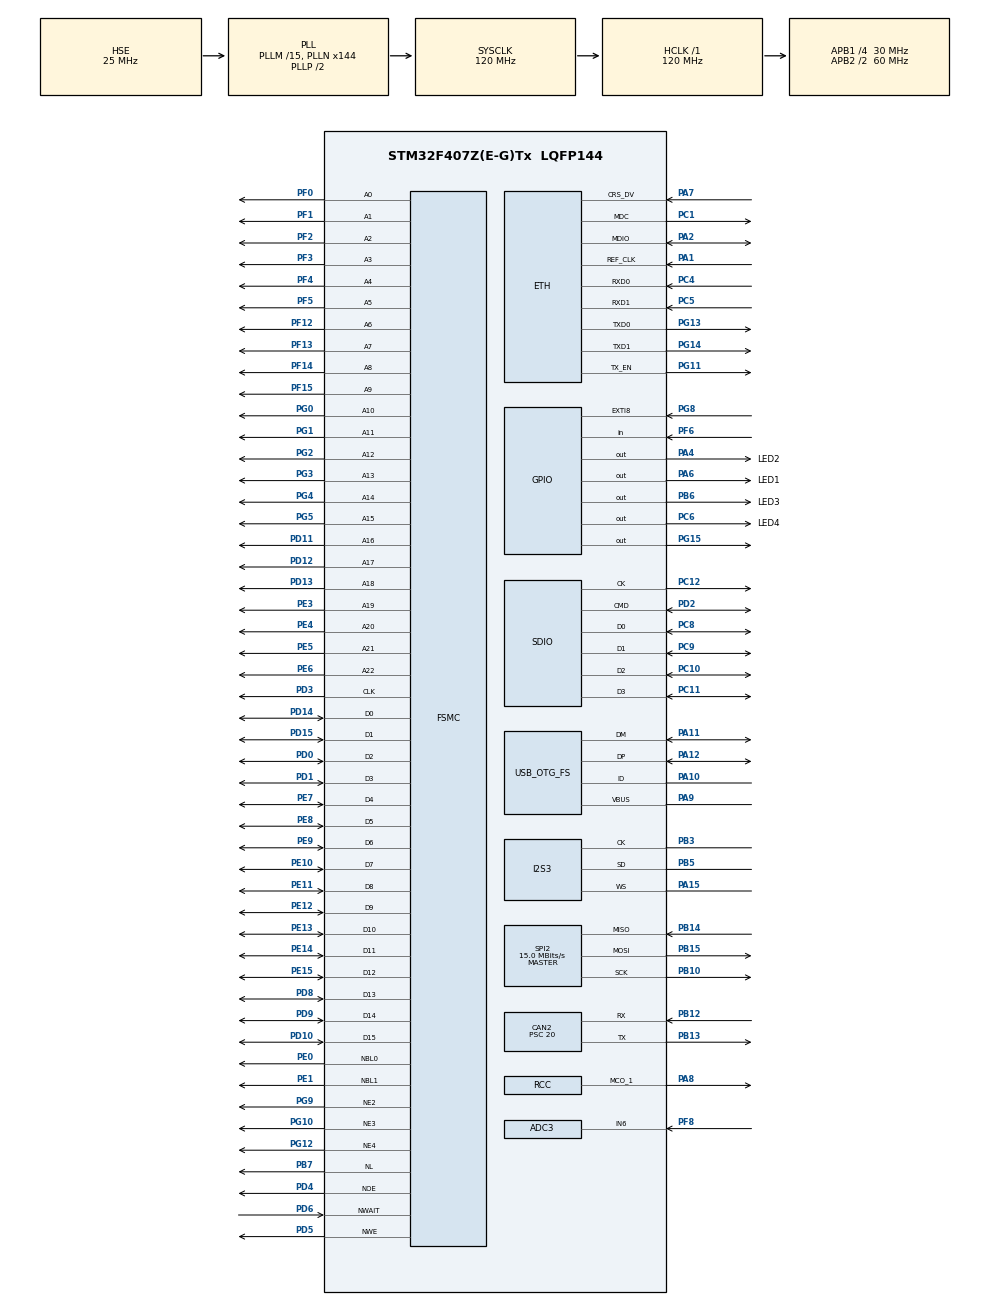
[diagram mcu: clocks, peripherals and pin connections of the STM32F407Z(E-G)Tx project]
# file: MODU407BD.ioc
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ADC3.Channel-0\#ChannelRegularConversion=ADC_CHANNEL_6
ADC3.NbrOfConversionFlag=1
ADC3.Rank-0\#ChannelRegularConversion=1
ADC3.SamplingTime-0\#ChannelRegularConversion=ADC_SAMPLETIME_3CYCLES
CAN2.CalculateBaudRate=499999
CAN2.CalculateTimeBit=2000
CAN2.CalculateTimeQuantum=666.6666666666667
CAN2.Prescaler=20
ETH.MediaInterface=ETH_MEDIA_INTERFACE_RMII
FATFS.BSP.number=1
FATFS0.BSP.STBoard=false
FATFS0.BSP.api=Unknown
FATFS0.BSP.i2caddr=0
FATFS0.BSP.instance=PF6
FATFS0.BSP.ip=GPIO
FATFS0.BSP.mode=Input
FATFS0.BSP.name=Detect_SDIO
FATFS0.BSP.solution=PF6
FREERTOS.Tasks01=mqttTask,0,512,startMqttTask,Default,NULL,Dynamic,NULL,NULL;dispTask,-1,512,startDispTask,Default,NULL,Dynamic,NULL,NULL
FREERTOS.configCHECK_FOR_STACK_OVERFLOW=2
FREERTOS.configENABLE_FPU=1
FREERTOS.configMINIMAL_STACK_SIZE=512
FREERTOS.configUSE_NEWLIB_REENTRANT=1
FSMC.AddressSetupTime1=1
FSMC.BusTurnAroundDuration1=1
FSMC.DataSetupTime1=1
I2S3.AudioFreq=I2S_AUDIOFREQ_48K
I2S3.ErrorAudioFreq=0.15 %
I2S3.FullDuplexMode=I2S_FULLDUPLEXMODE_DISABLE
I2S3.Instance=SPI$Index
I2S3.RealAudioFreq=48.076 KHz
I2S3.VirtualMode=I2S_MODE_SLAVE
LWIP.GATEWAY_ADDRESS=192.168.000.001
LWIP.IP_ADDRESS=192.168.000.018
LWIP.LWIP_AUTOIP=0
LWIP.LWIP_DHCP=0
LWIP.LWIP_DHCP_AUTOIP_COOP=0
LWIP.LWIP_DHCP_BOOTP_FILE=1
LWIP.LWIP_NETIF_EXT_STATUS_CALLBACK=1
LWIP.LWIP_NETIF_STATUS_CALLBACK=1
LWIP.LWIP_SO_RCVBUF=1
LWIP.NETMASK_ADDRESS=255.255.255.000
LWIP.Version=v2.1.2_Cube
Mcu.Family=STM32F4
Mcu.Name=STM32F407Z(E-G)Tx
Mcu.Package=LQFP144
NVIC.CAN2_RX0_IRQn=true\:5\:0\:false\:false\:true\:true\:true\:true
NVIC.ETH_IRQn=true\:5\:0\:false\:false\:true\:true\:false\:true
NVIC.PriorityGroup=NVIC_PRIORITYGROUP_4
NVIC.TIM1_UP_TIM10_IRQn=true\:5\:0\:false\:false\:true\:false\:true\:true
NVIC.TimeBase=TIM1_UP_TIM10_IRQn
NVIC.TimeBaseIP=TIM1
PA0-WKUP.Mode=SYS_WakeUp0
PA0-WKUP.Signal=SYS_WKUP
PA1.Mode=RMII
PA1.Signal=ETH_REF_CLK
PA10.Mode=OTG/Dual_Role_Device
PA10.Signal=USB_OTG_FS_ID
PA11.Mode=OTG/Dual_Role_Device
PA11.Signal=USB_OTG_FS_DM
PA12.Mode=OTG/Dual_Role_Device
PA12.Signal=USB_OTG_FS_DP
PA13.Mode=Serial_Wire
PA13.Signal=SYS_JTMS-SWDIO
PA14.Mode=Serial_Wire
PA14.Signal=SYS_JTCK-SWCLK
PA15.Mode=Half_Duplex_Slave
PA15.Signal=I2S3_WS
PA2.Mode=RMII
PA2.Signal=ETH_MDIO
PA4.GPIO_Label=LED2
PA4.PinState=GPIO_PIN_SET
PA4.Signal=GPIO_Output
PA6.GPIO_Label=LED1
PA6.PinState=GPIO_PIN_SET
PA6.Signal=GPIO_Output
PA7.Mode=RMII
PA7.Signal=ETH_CRS_DV
PA8.Mode=Clock-out-1
PA8.Signal=RCC_MCO_1
PA9.Mode=Activate_VBUS
PA9.Signal=USB_OTG_FS_VBUS
PB10.Mode=Full_Duplex_Master
PB10.Signal=SPI2_SCK
PB12.Mode=CAN_Activate
PB12.Signal=CAN2_RX
PB13.Mode=CAN_Activate
PB13.Signal=CAN2_TX
PB14.Mode=Full_Duplex_Master
PB14.Signal=SPI2_MISO
PB15.Mode=Full_Duplex_Master
PB15.Signal=SPI2_MOSI
PB3.Mode=Half_Duplex_Slave
PB3.Signal=I2S3_CK
PB5.Mode=Half_Duplex_Slave
PB5.Signal=I2S3_SD
PB6.GPIO_Label=LED3
PB6.PinState=GPIO_PIN_SET
PB6.Signal=GPIO_Output
PB7.Signal=FSMC_NL
PC1.Mode=RMII
PC1.Signal=ETH_MDC
PC10.Mode=SD_4_bits_Wide_bus
PC10.Signal=SDIO_D2
PC11.Mode=SD_4_bits_Wide_bus
PC11.Signal=SDIO_D3
PC12.Mode=SD_4_bits_Wide_bus
PC12.Signal=SDIO_CK
PC14-OSC32_IN.Mode=LSE-External-Oscillator
PC14-OSC32_IN.Signal=RCC_OSC32_IN
PC15-OSC32_OUT.Mode=LSE-External-Oscillator
PC15-OSC32_OUT.Signal=RCC_OSC32_OUT
PC4.Mode=RMII
PC4.Signal=ETH_RXD0
PC5.Mode=RMII
PC5.Signal=ETH_RXD1
PC6.GPIO_Label=LED4
PC6.PinState=GPIO_PIN_SET
PC6.Signal=GPIO_Output
PC8.Mode=SD_4_bits_Wide_bus
PC8.Signal=SDIO_D0
PC9.Mode=SD_4_bits_Wide_bus
PC9.Signal=SDIO_D1
PD0.Signal=FSMC_D2_DA2
PD1.Signal=FSMC_D3_DA3
PD10.Signal=FSMC_D15_DA15
PD11.Signal=FSMC_A16_CLE
PD12.Signal=FSMC_A17_ALE
PD13.Signal=FSMC_A18
PD14.Signal=FSMC_D0_DA0
PD15.Signal=FSMC_D1_DA1
PD2.Mode=SD_4_bits_Wide_bus
PD2.Signal=SDIO_CMD
PD3.Signal=FSMC_CLK
PD4.Signal=FSMC_NOE
PD5.Signal=FSMC_NWE
PD6.Signal=FSMC_NWAIT
PD8.Signal=FSMC_D13_DA13
PD9.Signal=FSMC_D14_DA14
PE0.Signal=FSMC_NBL0
PE1.Signal=FSMC_NBL1
PE10.Signal=FSMC_D7_DA7
PE11.Signal=FSMC_D8_DA8
PE12.Signal=FSMC_D9_DA9
PE13.Signal=FSMC_D10_DA10
PE14.Signal=FSMC_D11_DA11
PE15.Signal=FSMC_D12_DA12
PE3.Signal=FSMC_A19
PE4.Signal=FSMC_A20
PE5.Signal=FSMC_A21
PE6.Signal=FSMC_A22
PE7.Signal=FSMC_D4_DA4
PE8.Signal=FSMC_D5_DA5
PE9.Signal=FSMC_D6_DA6
PF0.Signal=FSMC_A0
PF1.Signal=FSMC_A1
PF12.Signal=FSMC_A6
PF13.Signal=FSMC_A7
PF14.Signal=FSMC_A8
PF15.Signal=FSMC_A9
PF2.Signal=FSMC_A2
PF3.Signal=FSMC_A3
PF4.Signal=FSMC_A4
PF5.Signal=FSMC_A5
PF6.Signal=GPIO_Input
PF8.Mode=IN6
PF8.Signal=ADC3_IN6
PG0.Signal=FSMC_A10
PG1.Signal=FSMC_A11
PG10.Mode=NorPsramChipSelect3_2
PG10.Signal=FSMC_NE3
PG11.Mode=RMII
PG11.Signal=ETH_TX_EN
PG12.Mode=NorPsramChipSelect4_1
PG12.Signal=FSMC_NE4
PG13.Mode=RMII
PG13.Signal=ETH_TXD0
PG14.Mode=RMII
PG14.Signal=ETH_TXD1
PG15.Signal=GPIO_Output
PG2.Signal=FSMC_A12
PG3.Signal=FSMC_A13
PG4.Signal=FSMC_A14
PG5.Signal=FSMC_A15
PG8.Signal=GPXTI8
PG9.Mode=NorPsramChipSelect2_3
PG9.Signal=FSMC_NE2
PH0-OSC_IN.Mode=HSE-External-Oscillator
PH0-OSC_IN.Signal=RCC_OSC_IN
PH1-OSC_OUT.Mode=HSE-External-Oscillator
PH1-OSC_OUT.Signal=RCC_OSC_OUT
ProjectManager.HeapSize=0x200
ProjectManager.StackSize=0x400
ProjectManager.TargetToolchain=STM32CubeIDE
RCC.48MHZClocksFreq_Value=48000000
RCC.AHBFreq_Value=120000000
RCC.APB1CLKDivider=RCC_HCLK_DIV4
RCC.APB1Freq_Value=30000000
RCC.APB1TimFreq_Value=60000000
RCC.APB2CLKDivider=RCC_HCLK_DIV2
RCC.APB2Freq_Value=60000000
RCC.APB2TimFreq_Value=120000000
RCC.CortexFreq_Value=120000000
RCC.HCLKFreq_Value=120000000
RCC.HSE_VALUE=25000000
RCC.HSI_VALUE=16000000
RCC.PLLI2SN=144
RCC.PLLM=15
RCC.PLLN=144
RCC.PLLQ=5
RCC.RCC_MCO1Source=RCC_MCO1SOURCE_PLLCLK
RCC.RCC_MCODiv1=RCC_MCODIV_5
RCC.RCC_RTC_Clock_Source=RCC_RTCCLKSOURCE_LSE
RCC.RCC_RTC_Clock_SourceVirtual=RCC_RTCCLKSOURCE_LSE
RCC.SYSCLKFreq_VALUE=120000000
RCC.SYSCLKSource=RCC_SYSCLKSOURCE_PLLCLK
RCC.VCOOutputFreq_Value=240000000
SH.FSMC_A0.0=FSMC_A0,A0_1
SH.FSMC_A0.1=FSMC_A0,18b-a2
SH.FSMC_A0.2=FSMC_A0,23b-a3
SH.FSMC_A1.0=FSMC_A1,18b-a2
SH.FSMC_A1.1=FSMC_A1,23b-a3
SH.FSMC_A10.0=FSMC_A10,18b-a2
SH.FSMC_A10.1=FSMC_A10,23b-a3
SH.FSMC_A11.0=FSMC_A11,18b-a2
SH.FSMC_A11.1=FSMC_A11,23b-a3
SH.FSMC_A12.0=FSMC_A12,18b-a2
SH.FSMC_A12.1=FSMC_A12,23b-a3
SH.FSMC_A13.0=FSMC_A13,18b-a2
SH.FSMC_A13.1=FSMC_A13,23b-a3
SH.FSMC_A14.0=FSMC_A14,18b-a2
SH.FSMC_A14.1=FSMC_A14,23b-a3
SH.FSMC_A15.0=FSMC_A15,18b-a2
SH.FSMC_A15.1=FSMC_A15,23b-a3
SH.FSMC_A16_CLE.0=FSMC_A16,18b-a2
SH.FSMC_A16_CLE.1=FSMC_A16,23b-a3
SH.FSMC_A17_ALE.0=FSMC_A17,18b-a2
SH.FSMC_A17_ALE.1=FSMC_A17,23b-a3
SH.FSMC_A18.0=FSMC_A18,23b-a3
SH.FSMC_A19.0=FSMC_A19,23b-a3
SH.FSMC_A2.0=FSMC_A2,18b-a2
SH.FSMC_A2.1=FSMC_A2,23b-a3
SH.FSMC_A20.0=FSMC_A20,23b-a3
SH.FSMC_A21.0=FSMC_A21,23b-a3
SH.FSMC_A22.0=FSMC_A22,23b-a3
SH.FSMC_A3.0=FSMC_A3,18b-a2
SH.FSMC_A3.1=FSMC_A3,23b-a3
SH.FSMC_A4.0=FSMC_A4,18b-a2
SH.FSMC_A4.1=FSMC_A4,23b-a3
SH.FSMC_A5.0=FSMC_A5,18b-a2
SH.FSMC_A5.1=FSMC_A5,23b-a3
SH.FSMC_A6.0=FSMC_A6,18b-a2
SH.FSMC_A6.1=FSMC_A6,23b-a3
SH.FSMC_A7.0=FSMC_A7,18b-a2
SH.FSMC_A7.1=FSMC_A7,23b-a3
SH.FSMC_A8.0=FSMC_A8,18b-a2
SH.FSMC_A8.1=FSMC_A8,23b-a3
SH.FSMC_A9.0=FSMC_A9,18b-a2
SH.FSMC_A9.1=FSMC_A9,23b-a3
SH.FSMC_CLK.0=FSMC_CLK,BurstRead3
SH.FSMC_D0_DA0.0=FSMC_D0,16b-d1
SH.FSMC_D0_DA0.1=FSMC_D0,16b-d2
SH.FSMC_D0_DA0.2=FSMC_D0,16b-d3
SH.FSMC_D10_DA10.0=FSMC_D10,16b-d1
SH.FSMC_D10_DA10.1=FSMC_D10,16b-d2
SH.FSMC_D10_DA10.2=FSMC_D10,16b-d3
SH.FSMC_D11_DA11.0=FSMC_D11,16b-d1
SH.FSMC_D11_DA11.1=FSMC_D11,16b-d2
SH.FSMC_D11_DA11.2=FSMC_D11,16b-d3
SH.FSMC_D12_DA12.0=FSMC_D12,16b-d1
SH.FSMC_D12_DA12.1=FSMC_D12,16b-d2
SH.FSMC_D12_DA12.2=FSMC_D12,16b-d3
SH.FSMC_D13_DA13.0=FSMC_D13,16b-d1
SH.FSMC_D13_DA13.1=FSMC_D13,16b-d2
SH.FSMC_D13_DA13.2=FSMC_D13,16b-d3
SH.FSMC_D14_DA14.0=FSMC_D14,16b-d1
SH.FSMC_D14_DA14.1=FSMC_D14,16b-d2
SH.FSMC_D14_DA14.2=FSMC_D14,16b-d3
SH.FSMC_D15_DA15.0=FSMC_D15,16b-d1
SH.FSMC_D15_DA15.1=FSMC_D15,16b-d2
SH.FSMC_D15_DA15.2=FSMC_D15,16b-d3
SH.FSMC_D1_DA1.0=FSMC_D1,16b-d1
SH.FSMC_D1_DA1.1=FSMC_D1,16b-d2
SH.FSMC_D1_DA1.2=FSMC_D1,16b-d3
SH.FSMC_D2_DA2.0=FSMC_D2,16b-d1
SH.FSMC_D2_DA2.1=FSMC_D2,16b-d2
SH.FSMC_D2_DA2.2=FSMC_D2,16b-d3
SH.FSMC_D3_DA3.0=FSMC_D3,16b-d1
SH.FSMC_D3_DA3.1=FSMC_D3,16b-d2
SH.FSMC_D3_DA3.2=FSMC_D3,16b-d3
SH.FSMC_D4_DA4.0=FSMC_D4,16b-d1
SH.FSMC_D4_DA4.1=FSMC_D4,16b-d2
SH.FSMC_D4_DA4.2=FSMC_D4,16b-d3
SH.FSMC_D5_DA5.0=FSMC_D5,16b-d1
SH.FSMC_D5_DA5.1=FSMC_D5,16b-d2
SH.FSMC_D5_DA5.2=FSMC_D5,16b-d3
SH.FSMC_D6_DA6.0=FSMC_D6,16b-d1
SH.FSMC_D6_DA6.1=FSMC_D6,16b-d2
SH.FSMC_D6_DA6.2=FSMC_D6,16b-d3
SH.FSMC_D7_DA7.0=FSMC_D7,16b-d1
SH.FSMC_D7_DA7.1=FSMC_D7,16b-d2
SH.FSMC_D7_DA7.2=FSMC_D7,16b-d3
SH.FSMC_D8_DA8.0=FSMC_D8,16b-d1
SH.FSMC_D8_DA8.1=FSMC_D8,16b-d2
SH.FSMC_D8_DA8.2=FSMC_D8,16b-d3
SH.FSMC_D9_DA9.0=FSMC_D9,16b-d1
SH.FSMC_D9_DA9.1=FSMC_D9,16b-d2
SH.FSMC_D9_DA9.2=FSMC_D9,16b-d3
SH.FSMC_NBL0.0=FSMC_NBL0,2ByteEnable2
SH.FSMC_NBL1.0=FSMC_NBL1,2ByteEnable2
SH.FSMC_NL.0=FSMC_NL,AddressValid3
SH.FSMC_NOE.0=FSMC_NOE,Lcd1
SH.FSMC_NOE.1=FSMC_NOE,Sram2
SH.FSMC_NOE.2=FSMC_NOE,NorFlash3
SH.FSMC_NWAIT.0=FSMC_NWAIT,AsynchronousWait2
SH.FSMC_NWE.0=FSMC_NWE,Lcd1
SH.FSMC_NWE.1=FSMC_NWE,Sram2
SH.FSMC_NWE.2=FSMC_NWE,NorFlash3
SPI2.CalculateBaudRate=15.0 MBits/s
SPI2.Direction=SPI_DIRECTION_2LINES
SPI2.Mode=SPI_MODE_MASTER
SPI2.VirtualType=VM_MASTER
TIM10.Period=999
TIM10.Prescaler=119
VP_FATFS_VS_SDIO.Mode=SDIO
VP_FREERTOS_VS_CMSIS_V1.Mode=CMSIS_V1
VP_LWIP_VS_Enabled.Mode=Enabled
VP_RTC_VS_RTC_Activate.Mode=RTC_Enabled
VP_SYS_VS_tim1.Mode=TIM1
VP_TIM10_VS_ClockSourceINT.Mode=Enable_Timer
VP_TIM14_VS_ClockSourceINT.Mode=Enable_Timer
board=custom

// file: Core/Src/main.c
/* USER CODE BEGIN Header */
/**
  ******************************************************************************
  * @file           : main.c
  * @brief          : Main program body
  ******************************************************************************
  * @attention
  *
  * Copyright (c) 2021 STMicroelectronics.
  * All rights reserved.
  *
  * This software is licensed under terms that can be found in the LICENSE file
  * in the root directory of this software component.
  * If no LICENSE file comes with this software, it is provided AS-IS.
  *
  ******************************************************************************
  */
/* USER CODE END Header */
#include "main.h"
#include "cmsis_os.h"
#include "adc.h"
#include "can.h"
#include "fatfs.h"
#include "i2s.h"
#include "lwip.h"
#include "rtc.h"
#include "sdio.h"
#include "spi.h"
#include "tim.h"
#include "usb_otg.h"
#include "gpio.h"
#include "fsmc.h"

/* USER CODE BEGIN Includes */
#include "display.h"

/* USER CODE END Includes */

/* USER CODE BEGIN PV */
extern uint32_t MilliTimer;
/* USER CODE END PV */

void SystemClock_Config(void);
void MX_FREERTOS_Init(void);

/* USER CODE BEGIN 0 */
int _write(int file, char *ptr, int len)
{
  int DataIdx;

  for (DataIdx = 0; DataIdx < len; DataIdx++)
  {
    ITM_SendChar(*ptr++);
  }
  return len;
}

/* USER CODE END 0 */

int main(void)
{

  /* MCU Configuration--------------------------------------------------------*/

  /* Reset of all peripherals, Initializes the Flash interface and the Systick. */
  HAL_Init();

  /* Configure the system clock */
  SystemClock_Config();

  /* Initialize all configured peripherals */
  MX_GPIO_Init();
  MX_RTC_Init();
  MX_USB_OTG_FS_USB_Init();
  MX_ADC3_Init();
  MX_CAN2_Init();
  MX_FSMC_Init();
  MX_I2S3_Init();
  MX_SPI2_Init();
  MX_TIM10_Init();
  MX_TIM14_Init();
  MX_SDIO_SD_Init();
  MX_FATFS_Init();
  /* USER CODE BEGIN 2 */

  printf("Don't remove this printf to prevent hard fault.\r\n");

  /* USER CODE END 2 */

  /* Call init function for freertos objects (in freertos.c) */
  MX_FREERTOS_Init();
  /* Start scheduler */
  osKernelStart();

  /* We should never get here as control is now taken by the scheduler */
  /* Infinite loop */
  while (1)
  {

  }
}

void SystemClock_Config(void)
{
  RCC_OscInitTypeDef RCC_OscInitStruct = {0};
  RCC_ClkInitTypeDef RCC_ClkInitStruct = {0};

  /** Configure the main internal regulator output voltage
  */
  __HAL_RCC_PWR_CLK_ENABLE();
  __HAL_PWR_VOLTAGESCALING_CONFIG(PWR_REGULATOR_VOLTAGE_SCALE1);
  /** Initializes the RCC Oscillators according to the specified parameters
  * in the RCC_OscInitTypeDef structure.
  */
  RCC_OscInitStruct.OscillatorType = RCC_OSCILLATORTYPE_HSE|RCC_OSCILLATORTYPE_LSE;
  RCC_OscInitStruct.HSEState = RCC_HSE_ON;
  RCC_OscInitStruct.LSEState = RCC_LSE_ON;
  RCC_OscInitStruct.PLL.PLLState = RCC_PLL_ON;
  RCC_OscInitStruct.PLL.PLLSource = RCC_PLLSOURCE_HSE;
  RCC_OscInitStruct.PLL.PLLM = 15;
  RCC_OscInitStruct.PLL.PLLN = 144;
  RCC_OscInitStruct.PLL.PLLP = RCC_PLLP_DIV2;
  RCC_OscInitStruct.PLL.PLLQ = 5;
  if (HAL_RCC_OscConfig(&RCC_OscInitStruct) != HAL_OK)
  {
    Error_Handler();
  }
  /** Initializes the CPU, AHB and APB buses clocks
  */
  RCC_ClkInitStruct.ClockType = RCC_CLOCKTYPE_HCLK|RCC_CLOCKTYPE_SYSCLK
                              |RCC_CLOCKTYPE_PCLK1|RCC_CLOCKTYPE_PCLK2;
  RCC_ClkInitStruct.SYSCLKSource = RCC_SYSCLKSOURCE_PLLCLK;
  RCC_ClkInitStruct.AHBCLKDivider = RCC_SYSCLK_DIV1;
  RCC_ClkInitStruct.APB1CLKDivider = RCC_HCLK_DIV4;
  RCC_ClkInitStruct.APB2CLKDivider = RCC_HCLK_DIV2;

  if (HAL_RCC_ClockConfig(&RCC_ClkInitStruct, FLASH_LATENCY_3) != HAL_OK)
  {
    Error_Handler();
  }
  HAL_RCC_MCOConfig(RCC_MCO1, RCC_MCO1SOURCE_PLLCLK, RCC_MCODIV_5);
}

void HAL_TIM_PeriodElapsedCallback(TIM_HandleTypeDef *htim)
{
  if (htim->Instance == TIM1) {
    HAL_IncTick();
  }
  /* USER CODE BEGIN Callback 1 */
  if(htim->Instance ==TIM10)
  {
	// LVGL Timer Tick 1ms
	lv_tick_inc(1);

	MilliTimer++;
  }

  /* USER CODE END Callback 1 */
}

void Error_Handler(void)
{
  __disable_irq();
  while (1)
  {
  }
}

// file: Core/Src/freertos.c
/* USER CODE BEGIN Header */
/**
  ******************************************************************************
  * File Name          : freertos.c
  * Description        : Code for freertos applications
  ******************************************************************************
  * @attention
  *
  * Copyright (c) 2022 STMicroelectronics.
  * All rights reserved.
  *
  * This software is licensed under terms that can be found in the LICENSE file
  * in the root directory of this software component.
  * If no LICENSE file comes with this software, it is provided AS-IS.
  *
  ******************************************************************************
  */
/* USER CODE END Header */

#include "FreeRTOS.h"
#include "task.h"
#include "main.h"
#include "cmsis_os.h"

/* USER CODE BEGIN Includes */
#include "device.h"

#include <string.h>
#include "lwip.h"
#include "lwip/api.h"
#include "MQTTClient.h"
#include "MQTTInterface.h"

/* USER CODE END Includes */

/* USER CODE BEGIN PD */
#define BROKER_IP		"13.125.31.75"
#define MQTT_PORT		1883
#define MQTT_BUFSIZE	1024

/* USER CODE END PD */

/* USER CODE BEGIN Variables */
extern struct netif gnetif;

osThreadId mqttClientSubTaskHandle;  //mqtt client task handle
osThreadId mqttClientPubTaskHandle;  //mqtt client task handle

Network net;
MQTTClient mqttClient;

uint8_t sndBuffer[MQTT_BUFSIZE]; //mqtt send buffer
uint8_t rcvBuffer[MQTT_BUFSIZE]; //mqtt receive buffer
uint8_t msgBuffer[MQTT_BUFSIZE]; //mqtt message buffer

/* USER CODE END Variables */
osThreadId mqttTaskHandle;
osThreadId dispTaskHandle;

/* USER CODE BEGIN FunctionPrototypes */
void MqttClientSubTask(void const *argument);	//mqtt client subscribe task function
void MqttClientPubTask(void const *argument);	//mqtt client publish task function
int  MqttConnectBroker(void);					//mqtt broker connect function
void MqttMessageArrived(MessageData* msg);		//mqtt message callback function

/* USER CODE END FunctionPrototypes */

void startMqttTask(void const * argument);
void startDispTask(void const * argument);

extern void MX_LWIP_Init(void);
void MX_FREERTOS_Init(void); /* (MISRA C 2004 rule 8.1) */

/* GetIdleTaskMemory prototype (linked to static allocation support) */
void vApplicationGetIdleTaskMemory( StaticTask_t **ppxIdleTaskTCBBuffer, StackType_t **ppxIdleTaskStackBuffer, uint32_t *pulIdleTaskStackSize );

/* Hook prototypes */
void vApplicationStackOverflowHook(xTaskHandle xTask, signed char *pcTaskName);

/* USER CODE BEGIN 4 */
__weak void vApplicationStackOverflowHook(xTaskHandle xTask, signed char *pcTaskName)
{
   /* Run time stack overflow checking is performed if
   configCHECK_FOR_STACK_OVERFLOW is defined to 1 or 2. This hook function is
   called if a stack overflow is detected. */

	HAL_GPIO_WritePin(LED2_GPIO_Port, LED2_Pin, GPIO_PIN_SET);
}
/* USER CODE END 4 */

/* USER CODE BEGIN GET_IDLE_TASK_MEMORY */
static StaticTask_t xIdleTaskTCBBuffer;
static StackType_t xIdleStack[configMINIMAL_STACK_SIZE];

void vApplicationGetIdleTaskMemory( StaticTask_t **ppxIdleTaskTCBBuffer, StackType_t **ppxIdleTaskStackBuffer, uint32_t *pulIdleTaskStackSize )
{
  *ppxIdleTaskTCBBuffer = &xIdleTaskTCBBuffer;
  *ppxIdleTaskStackBuffer = &xIdleStack[0];
  *pulIdleTaskStackSize = configMINIMAL_STACK_SIZE;
  /* place for user code */
}
/* USER CODE END GET_IDLE_TASK_MEMORY */

void MX_FREERTOS_Init(void) {

  /* USER CODE BEGIN RTOS_MUTEX */

  /* Create Mutex */
  //pthread_mutex_init(&lvgl_mutex, NULL);

  /* USER CODE END RTOS_MUTEX */

  /* Create the thread(s) */
  /* definition and creation of mqttTask */
  osThreadDef(mqttTask, startMqttTask, osPriorityNormal, 0, 512);
  mqttTaskHandle = osThreadCreate(osThread(mqttTask), NULL);

  /* definition and creation of dispTask */
  osThreadDef(dispTask, startDispTask, osPriorityBelowNormal, 0, 512);
  dispTaskHandle = osThreadCreate(osThread(dispTask), NULL);

}

void startMqttTask(void const * argument)
{
  /* init code for LWIP */
  MX_LWIP_Init();
  /* USER CODE BEGIN startMqttTask */

	osThreadDef(mqttClientSubTask, MqttClientSubTask, osPriorityNormal, 0, 512); //subscribe task
	osThreadDef(mqttClientPubTask, MqttClientPubTask, osPriorityNormal, 0, 512); //publish task
	mqttClientSubTaskHandle = osThreadCreate(osThread(mqttClientSubTask), NULL);
	mqttClientPubTaskHandle = osThreadCreate(osThread(mqttClientPubTask), NULL);

  /* Infinite loop */
  for(;;)
  {
    osDelay(1);
  }
  /* USER CODE END startMqttTask */
}

void startDispTask(void const * argument)
{
  /* USER CODE BEGIN startDispTask */
  display_init();

  /* Infinite loop */
  for(;;)
  {
    lv_task_handler();

    osDelay(10);
  }
  /* USER CODE END startDispTask */
}

/* USER CODE BEGIN Application */

void MqttClientSubTask(void const *argument)
{
	while(1)
	{
		//waiting for valid ip address
		if (gnetif.ip_addr.addr == 0 || gnetif.netmask.addr == 0 || gnetif.gw.addr == 0) //system has no valid ip address
		{
			osDelay(1000);
			continue;
		}
		else
		{
			printf("DHCP/Static IP O.K.\n");
			break;
		}
	}

	while(1)
	{
		if(!mqttClient.isconnected)
		{
			//try to connect to the broker
			MQTTDisconnect(&mqttClient);
			MqttConnectBroker();
			osDelay(1000);
		}
		else
		{
			MQTTYield(&mqttClient, 1000); //handle timer
			osDelay(100);
		}
	}
}

void MqttClientPubTask(void const *argument)
{
	const char* str = "MQTT message from STM32";
	MQTTMessage message;

	while(1)
	{
		if(mqttClient.isconnected)
		{
			message.payload = (void*)str;
			message.payloadlen = strlen(str);

			MQTTPublish(&mqttClient, "test", &message); //publish a message
		}

		osDelay(1000);
	}
}

void mqttClientPubTask(void const * argument)
{
/* USER CODE BEGIN startMqttPupTask */
/* Infinite loop */
	const char* str = "MQTT message from STM32";
	MQTTMessage message;

	while(1)
	{
		if(mqttClient.isconnected)
		{
			message.payload = (void*)str;
			message.payloadlen = strlen(str);

			MQTTPublish(&mqttClient, "", &message); //publish a message
		}

		osDelay(1000);
	}
/* USER CODE END startMqttPupTask */
}

int MqttConnectBroker()
{
	int ret;

	NewNetwork(&net);
	ret = ConnectNetwork(&net, BROKER_IP, MQTT_PORT);
	if(ret != MQTT_SUCCESS)
	{
		printf("ConnectNetwork failed.\n");
		return -1;
	}

	MQTTClientInit(&mqttClient, &net, 1000, sndBuffer, sizeof(sndBuffer), rcvBuffer, sizeof(rcvBuffer));

	MQTTPacket_connectData data = MQTTPacket_connectData_initializer;
	data.willFlag = 0;
	data.MQTTVersion = 3;
	data.clientID.cstring = "STM32F4";
	data.username.cstring = "STM32F4";
	data.password.cstring = "";
	data.keepAliveInterval = 60;
	data.cleansession = 1;

	ret = MQTTConnect(&mqttClient, &data);
	if(ret != MQTT_SUCCESS)
	{
		printf("MQTTConnect failed.\n");
		return ret;
	}

	ret = MQTTSubscribe(&mqttClient, "test", QOS0, MqttMessageArrived);
	if(ret != MQTT_SUCCESS)
	{
		printf("MQTTSubscribe failed.\n");
		return ret;
	}

	printf("MQTT_ConnectBroker O.K.\n");
	return MQTT_SUCCESS;
}

void MqttMessageArrived(MessageData* msg)
{
	MQTTMessage* message = msg->message;
	memset(msgBuffer, 0, sizeof(msgBuffer));
	memcpy(msgBuffer, message->payload,message->payloadlen);

	printf("MQTT MSG[%d]:%s\n", (int)message->payloadlen, msgBuffer);
}

/* USER CODE END Application */
